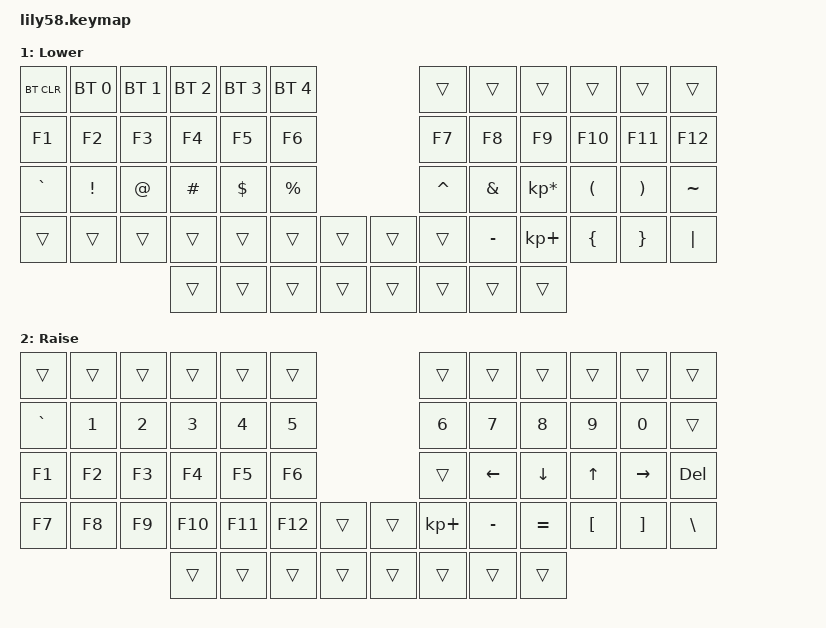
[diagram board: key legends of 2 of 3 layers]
/*
 * Copyright (c) 2020 The ZMK Contributors
 *
 * SPDX-License-Identifier: MIT
 */

#include <behaviors.dtsi>
#include <dt-bindings/zmk/keys.h>
#include <dt-bindings/zmk/bt.h>
#include <dt-bindings/zmk/ext_power.h>

#define HRML(k1,k2,k3,k4) &ht LALT k1  &ht LCTRL k2  &ht LGUI k3  &ht LSHFT k4
#define HRMR(k1,k2,k3,k4) &ht RSHFT k1  &ht RGUI k2  &ht RCTRL k3  &ht RALT k4

/ {
    behaviors {
        ht: hold_tap {
            compatible = "zmk,behavior-hold-tap";
            #binding-cells = <2>;
            flavor = "tap-preferred";
            tapping-term-ms = <150>;
            quick-tap-ms = <0>;
            bindings = <&kp>, <&kp>;
        };
         td0: tap_dance_0 {
            compatible = "zmk,behavior-tap-dance";
            #binding-cells = <0>;
            tapping-term-ms = <160>;
            bindings = <&kp Y>, <&kp ESC>;
        };
    };
    keymap {
        compatible = "zmk,keymap";

        default_layer {
            display-name = "Base";
            bindings = <
// ------------------------------------------------------------------------------------------------------------
// |  ESC  |  1  |  2  |  3   |  4   |  5   |                   |  6   |  7    |  8    |  9   |   0   |   `   |
&kp ESC   &kp N1 &kp N2 &kp N3   &kp N4   &kp N5                     &kp N6 &kp N7   &kp N8    &kp N9  &kp N0   &kp GRAVE
// |  TAB  |  Q  |  W  |  E   |  R   |  T   |                   |  Y   |  U    |  I    |  O   |   P   |   -   |
&kp TAB   &kp Q  &kp W  &kp E    &kp R    &kp T                      &td0 Y  &kp U    &kp I     &kp O   &kp P    &kp MINUS
// |  CTRL |  A  |  S  |  D   |  F   |  G   |                   |  H   |  J    |  K    |  L   |   ;   |   '   |
&kp LCTRL HRML(A,   S,    D,     F)    &kp G                      &kp H  HRMR(J,  K,      L,      ;)    &kp SQT
// | SHIFT |  Z  |  X  |  C   |  V   |  B   |   "["  |  |  "]"  |  N   |  M    |  ,    |  .   |   /   | SHIFT |
&kp LSHFT &kp Z  &kp X  &kp C    &kp V    &kp B  &kp LBKT   &kp RBKT &kp N  &kp M    &kp COMMA &kp DOT &kp FSLH &kp RSHFT
//                     | ALT  | GUI  | LOWER|  SPACE |  | ENTER | RAISE| BSPC  | GUI   |
                        &kp LALT &kp LGUI &mo 1  &kp SPACE  &kp RET  &mo 2  &kp BSPC &kp RGUI
            >;

            sensor-bindings = <&inc_dec_kp C_VOL_UP C_VOL_DN>;
        };

        lower_layer {
// ------------------------------------------------------------------------------------------------------------
// | BTCLR | BT1 | BT2 |  BT3 |  BT4 |  BT5 |                   |      |       |       |      |       |       |
// |  F1   |  F2 |  F3 |  F4  |  F5  |  F6  |                   |  F7  |  F8   |  F9   |  F10 |  F11  |  F12  |
// |   `   |  !  |  @  |  #   |  $   |  %   |                   |  ^   |  &    |  *    |  (   |   )   |   ~   |
// |       |     |     |      |      |      |        |  |       |      |  _    |  +    |  {   |   }   |  "|"  |
//                     |      |      |      |        |  |       |      |       |       |
            display-name = "Lower";
            bindings = <
&bt BT_CLR &bt BT_SEL 0     &bt BT_SEL 1      &bt BT_SEL 2      &bt BT_SEL 3 &bt BT_SEL 4                 &trans    &trans    &trans          &trans    &trans    &trans
&kp F1     &kp F2           &kp F3            &kp F4            &kp F5       &kp F6                       &kp F7    &kp F8    &kp F9          &kp F10   &kp F11   &kp F12
&kp GRAVE  &kp EXCL         &kp AT            &kp HASH          &kp DOLLAR   &kp PRCNT                    &kp CARET &kp AMPS  &kp KP_MULTIPLY &kp LPAR  &kp RPAR  &kp TILDE
&trans     &trans           &trans            &trans            &trans       &trans    &trans   &trans    &trans    &kp MINUS &kp KP_PLUS     &kp LBRC  &kp RBRC  &kp PIPE
                                              &trans            &trans       &trans    &trans   &trans    &trans    &trans    &trans
            >;

            sensor-bindings = <&inc_dec_kp C_VOL_UP C_VOL_DN>;
        };

        raise_layer {
// ------------------------------------------------------------------------------------------------------------
// |       |     |     |      |      |      |                   |      |       |       |      |       |       |
// |   `   |  1  |  2  |  3   |  4   |  5   |                   |  6   |   7   |   8   |  9   |   0   |       |
// |   F1  |  F2 |  F3 |  F4  |  F5  |  F6  |                   |      |   <-  |   v   |  ^   |  ->   |       |
// |   F7  |  F8 |  F9 |  F10 |  F11 |  F12 |        |  |       |  +   |   -   |   =   |  [   |   ]   |   \   |
//                     |      |      |      |        |  |       |      |       |       |
            display-name = "Raise";
            bindings = <
&trans    &trans &trans &trans  &trans  &trans                       &trans      &trans    &trans    &trans   &trans    &trans
&kp GRAVE &kp N1 &kp N2 &kp N3  &kp N4  &kp N5                       &kp N6      &kp N7    &kp N8    &kp N9   &kp N0    &trans
&kp F1    &kp F2 &kp F3 &kp F4  &kp F5  &kp F6                       &trans      &kp LEFT  &kp DOWN  &kp UP   &kp RIGHT &kp DEL
&kp F7    &kp F8 &kp F9 &kp F10 &kp F11 &kp F12   &trans   &trans    &kp KP_PLUS &kp MINUS &kp EQUAL &kp LBKT &kp RBKT  &kp BSLH
                        &trans  &trans  &trans    &trans   &trans    &trans      &trans    &trans
            >;

            sensor-bindings = <&inc_dec_kp C_VOL_UP C_VOL_DN>;
        };
    };
};
